# DSPIC33FJ16MC101 register map
Vendor: Microchip
Registers are 16-bit, read-write, reset 0x0 unless marked. A register's access mark holds for its fields unless they carry their own. Addresses are absolute, and some are shared; only a register's first bit layout is shown; [hi:lo] are bit positions.

## CONFIG — Configuration words, addresses in ProgramSpace
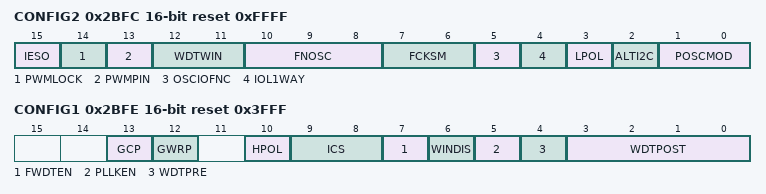
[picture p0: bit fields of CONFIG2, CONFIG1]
0x2BFC CONFIG2 reset 0xFFFF
  [15] IESO — Internal External Switch Over Mode
    0=OFF (Start-up device with user-selected oscillator source); 1=ON (Start-up device with FRC, then automatically switch to user-selected oscillator source when ready)
  [14] PWMLOCK — PWM Lock Enable
    1=ON (Certain PWM registers may only be written after key sequence); 0=OFF (PWM registers may be written without key sequence)
  [13] PWMPIN — Motor Control PWM Module Pin Mode bit
    1=ON (PWM module pins controlled by PORT register at device Reset); 0=OFF (PWM module pins controlled by PWM module at device Reset)
  [12:11] WDTWIN — Watchdog Window Select
    3=Watchdog Window is 25% of WDT period; 2=Watchdog Window is 37.5% of WDT period; 1=Watchdog Window is 50% of WDT period; 0=Watchdog Window is 75% of WDT period
  [10:8] FNOSC — Oscillator Mode
    0=FRC (Internal Fast RC (FRC)); 1=FRCPLL (Internal Fast RC (FRC) w/ PLL); 2=PRI (Primary Oscillator (MS, HS, EC)); 3=PRIPLL (Primary Oscillator (MS, HS, EC) w/ PLL); 4=SOSC (Secondary Oscillator (SOSC)); 5=LPRC (Low Power RC Oscillator (LPRC)); 7=FRCDIVN (Internal Fast RC (FRC) with divide by N)
  [7:6] FCKSM — Clock Switching and Monitor
    0b1x=CSDCMD (Clock switching and Fail-Safe Clock Monitor are disabled); 1=CSECMD (Clock switching is enabled, Fail-Safe Clock Monitor is disabled); 0=CSECME (Clock switching is enabled, Fail-Safe Clock Monitor is enabled)
  [5] OSCIOFNC — Primary Oscillator Output Function
    0=ON (OSC2 pin has digital I/O function); 1=OFF (OSC2 pin has clock out function)
  [4] IOL1WAY — IOLOCK Protection
    0=OFF (Allow Multiple Re-configurations); 1=ON (Allow Only One Re-configuration)
  [3] LPOL — Motor Control PWM Low Side Polarity bit
    1=ON (PWM module low side output pins have active-high output polarity); 0=OFF (PWM module low side output pins have active-low output polarity)
  [2] ALTI2C ro — Alternate I2C pins
    1=OFF (I2C mapped to SDA1/SCL1); 0=ON (I2C mapped to ASDA1/ASCL1)
  [1:0] POSCMOD — Primary Oscillator Select
    3=NONE (Primary oscillator disabled); 2=HS (HS Oscillator mode selected); 1=MS (MS Oscillator mode selected); 0=EC (EC Oscillator mode selected)
0x2BFE CONFIG1 reset 0x3FFF
  [13] GCP — General Segment Code Protection
    1=OFF (General Segment Code protect is disabled); 0=ON (Standard Security Code protection Enabled)
  [12] GWRP — General Code Segment Write Protect
    1=OFF (Writes to program memory are allowed); 0=ON (Writes to program memory are disabled)
  [10] HPOL — Motor Control PWM High Side Polarity bit
    1=ON (PWM module high side output pins have active-high output polarity); 0=OFF (PWM module high side output pins have active-low output polarity)
  [9:8] ICS — Comm Channel Select
    3=PGD1 (Communicate on PGEC1/PGED1); 2=PGD2 (Communicate on PGEC2/PGED2); 1=PGD3 (Communicate on PGEC3/PGED3)
  [7] FWDTEN — Watchdog Timer Enable
    1=ON (Watchdog timer always enabled); 0=OFF (Watchdog timer enabled/disabled by user software)
  [6] WINDIS — Watchdog Timer Window
    1=OFF (Watchdog Timer in Non-Window mode); 0=ON (Watchdog Timer in Window mode)
  [5] PLLKEN — PLL Lock Enable
    1=ON (Clock switch to PLL source will wait until the PLL lock signal is valid.); 0=OFF (Clock switch will not wait for the PLL lock signal.)
  [4] WDTPRE — WDT Prescaler
    1=PR128 (Prescaler ratio of 1:128); 0=PR32 (Prescaler ratio of 1:32)
  [3:0] WDTPOST — Watchdog Timer Postscaler
    15=PS32768 (1:32,768); 14=PS16384 (1:16,384); 13=PS8192 (1:8,192); 12=PS4096 (1:4,096); 11=PS2048 (1:2,048); 10=PS1024 (1:1,024); 9=PS512 (1:512); 8=PS256 (1:256); 7=PS128 (1:128); 6=PS64 (1:64); 5=PS32 (1:32); 4=PS16 (1:16); 3=PS8 (1:8); 2=PS4 (1:4); 1=PS2 (1:2); 0=PS1 (1:1)
